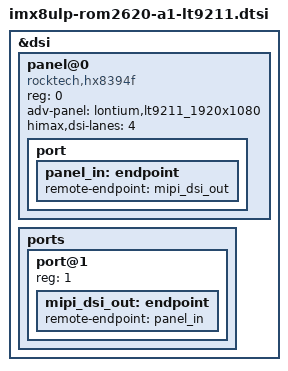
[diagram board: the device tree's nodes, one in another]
// SPDX-License-Identifier: GPL-2.0+
/*
 * Copyright 2022 NXP
 */

#include <dt-bindings/display/dt-media-bus-format.h>

&dsi {
	status = "okay";

        panel@0 {
                compatible = "rocktech,hx8394f";
                reg = <0>;
		adv-panel = "lontium,lt9211_1920x1080";
		//adv-panel = "lontium,lt9211_800x480";
		himax,dsi-lanes = <4>;

                port {
                        panel_in: endpoint {
                                remote-endpoint = <&mipi_dsi_out>;
                        };
                };
        };

        ports {
                port@1 {
                        reg = <1>;

                        mipi_dsi_out: endpoint {
                                remote-endpoint = <&panel_in>;
                        };
                };
        };
};

